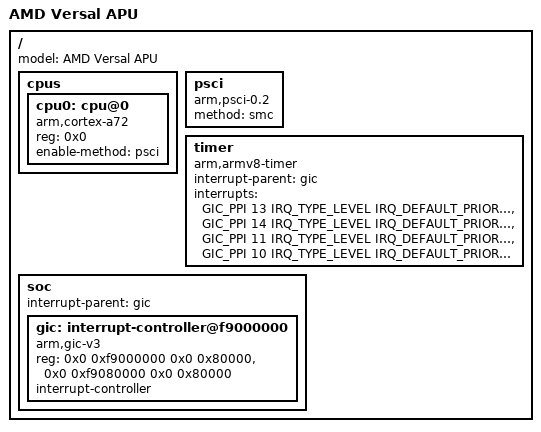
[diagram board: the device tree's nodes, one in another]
/*
 * Copyright (c) 2025, Advanced Micro Devices, Inc.
 *
 * SPDX-License-Identifier: Apache-2.0
 */

/dts-v1/;

#include <mem.h>
#include <arm64/armv8-a.dtsi>
#include <zephyr/dt-bindings/interrupt-controller/arm-gic.h>
#include <amd/versal_apu.dtsi>

/ {
	model = "AMD Versal APU";
	#address-cells = <2>;
	#size-cells = <2>;

	cpus {
		#address-cells = <1>;
		#size-cells = <0>;

		cpu0: cpu@0 {
			device_type = "cpu";
			compatible = "arm,cortex-a72";
			reg = <0x0>;
			enable-method = "psci";
		};
	};

	psci {
		compatible = "arm,psci-0.2", "arm,psci";
		method = "smc";
	};

	timer {
		compatible = "arm,armv8-timer";
		interrupt-parent = <&gic>;
		interrupts = <GIC_PPI 13 IRQ_TYPE_LEVEL IRQ_DEFAULT_PRIORITY>,
			     <GIC_PPI 14 IRQ_TYPE_LEVEL IRQ_DEFAULT_PRIORITY>,
			     <GIC_PPI 11 IRQ_TYPE_LEVEL IRQ_DEFAULT_PRIORITY>,
			     <GIC_PPI 10 IRQ_TYPE_LEVEL IRQ_DEFAULT_PRIORITY>;
	};

	soc {
		interrupt-parent = <&gic>;

		gic: interrupt-controller@f9000000 {
			compatible = "arm,gic-v3", "arm,gic";
			reg = <0x0 0xf9000000 0x0 0x80000>,
			      <0x0 0xf9080000 0x0 0x80000>;
			interrupt-controller;
			#interrupt-cells = <4>;
		};
	};
};
